# STM32L552xx register map
File version: 1.0
Registers are 32-bit, read-write, reset 0x0 unless marked. A register's access mark holds for its fields unless they carry their own. Offsets are from the block's base; [hi:lo] are bit positions.

## OPAMP12_COMMON
Base 0x40007800
Same registers: OPAMP12_COMMON_S 0x50007800
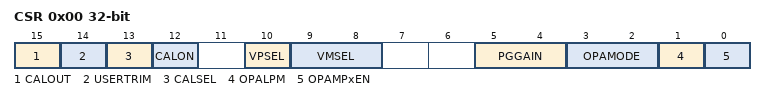
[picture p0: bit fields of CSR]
0x00 CSR — OPAMP control/status register, used for bits common to several OPAMP instances
  [15] CALOUT — Operational amplifier1 calibration output
  [14] USERTRIM — User trimming enable
    0=FACTORY (OPAMP trimming factors set to factory values); 1=USER (OPAMP trimming factors set to user values)
  [13] CALSEL — Calibration selection
  [12] CALON — Calibration mode enable
    0=FUNCTIONAL (OPAMP functional mode); 1=CALIBRATION (OPAMP calibration mode)
  [10] VPSEL — Non inverted input selection
    0=NONINVERT_IO0 (OPAMP non inverting input connected to GPIO pin (pin PA0 for OPAMP1, pin PA6 for OPAMP2)); 1=NONINV_DAC1_CH1 (OPAMP non inverting input connected to DAC1 channel1 output)
  [9:8] VMSEL — Inverting input selection
    0=IO0 (OPAMP inverting input connected to GPIO pin (valid also in PGA mode for filtering). Note: OPAMP inverting input is used with OPAMP in mode standalone or PGA with external capacitors for filtering circuit. Otherwise (OPAMP in mode follower), OPAMP inverting input is not used (not connected to GPIO pin).); 1=IO1 (OPAMP inverting input (low leakage input) connected to GPIO pin (available only on package BGA132). Note: OPAMP inverting input is used with OPAMP in mode standalone or PGA with external capacitors for filtering circuit. Otherwise (OPAMP in mode follower), OPAMP inverting input is not used (not connected to GPIO pin).); 2=CONNECT_NO (OPAMP inverting input not externally connected (intended for OPAMP in mode follower or PGA without external capacitors for filtering))
  [5:4] PGGAIN — Operational amplifier Programmable amplifier gain value
    0=GAIN_2 (OPAMP PGA gain 2); 1=GAIN_4 (OPAMP PGA gain 4); 2=GAIN_8 (OPAMP PGA gain 8); 3=GAIN_16 (OPAMP PGA gain 16)
  [3:2] OPAMODE — Operational amplifier PGA mode
    0=STANDALONE (OPAMP functional mode, OPAMP operation in standalone); 3=FOLLOWER (OPAMP functional mode, OPAMP operation in follower); 2=PGA (OPAMP functional mode, OPAMP operation in PGA)
  [1] OPALPM — Operational amplifier Low Power Mode
  [0] OPAMPxEN — OPAMP enable

## OPAMP1 — Operational Amplifier (OPAMP)
Base 0x40007800; alternate view of OPAMP12_COMMON
Same registers: OPAMP1_S 0x50007800 (alternate view of OPAMP12_COMMON_S)
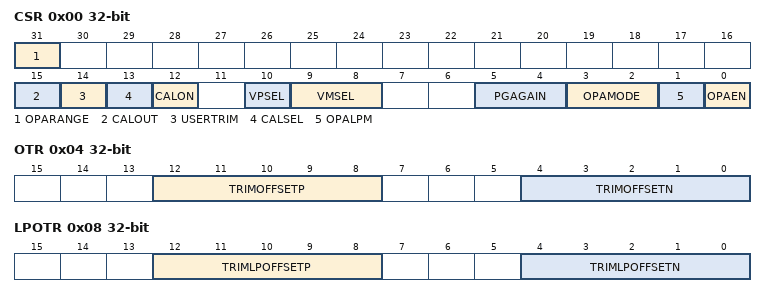
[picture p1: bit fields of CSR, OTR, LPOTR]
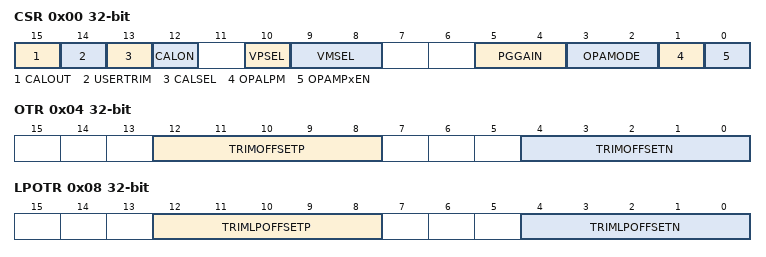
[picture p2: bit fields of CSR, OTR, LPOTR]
0x00 CSR — OPAMP control/status register
  [31] OPARANGE — Common to several OPAMP instances: Operational amplifier voltage supply range. Bit intended to be used with OPAMP common instance (OPAMP_Common_TypeDef)
    0=LOW (Power supply range low. On STM32L5 series: Vdda lower than 2.4V.); 1=HIGH (Power supply range high. On STM32L5 series: Vdda higher than 2.4V.)
  [15] CALOUT — Operational amplifier1 calibration output
  [14] USERTRIM — User trimming enable
  [13] CALSEL — Calibration selection
  [12] CALON — Calibration mode enable
  [10] VPSEL — Non inverted input selection
  [9:8] VMSEL — Inverting input selection
  [5:4] PGAGAIN — Operational amplifier1 Programmable amplifier gain value
  [3:2] OPAMODE — Operational amplifier1 PGA mode
  [1] OPALPM — Operational amplifier1 Low Power Mode
  [0] OPAEN — Operational amplifier1 Enable
0x04 OTR — OPAMP
  [12:8] TRIMOFFSETP — Trim for PMOS differential pairs
  [4:0] TRIMOFFSETN — Trim for NMOS differential pairs
0x08 LPOTR — OPAMP
  [12:8] TRIMLPOFFSETP — Trim for PMOS differential pairs
  [4:0] TRIMLPOFFSETN — Trim for NMOS differential pairs

## OPAMP — Operational Amplifier (OPAMP)
Base 0x40007800; alternate view of OPAMP12_COMMON
Same registers: OPAMP_S 0x50007800 (alternate view of OPAMP12_COMMON_S)
0x00 CSR — OPAMP control/status register
  [15] CALOUT — Operational amplifier1 calibration output
  [14] USERTRIM — User trimming enable
    0=FACTORY (OPAMP trimming factors set to factory values); 1=USER (OPAMP trimming factors set to user values)
  [13] CALSEL — Calibration selection
  [12] CALON — Calibration mode enable
    0=FUNCTIONAL (OPAMP functional mode); 1=CALIBRATION (OPAMP calibration mode)
  [10] VPSEL — Non inverted input selection
    0=NONINVERT_IO0 (OPAMP non inverting input connected to GPIO pin (pin PA0 for OPAMP1, pin PA6 for OPAMP2)); 1=NONINV_DAC1_CH1 (OPAMP non inverting input connected to DAC1 channel1 output)
  [9:8] VMSEL — Inverting input selection
    0=IO0 (OPAMP inverting input connected to GPIO pin (valid also in PGA mode for filtering). Note: OPAMP inverting input is used with OPAMP in mode standalone or PGA with external capacitors for filtering circuit. Otherwise (OPAMP in mode follower), OPAMP inverting input is not used (not connected to GPIO pin).); 1=IO1 (OPAMP inverting input (low leakage input) connected to GPIO pin (available only on package BGA132). Note: OPAMP inverting input is used with OPAMP in mode standalone or PGA with external capacitors for filtering circuit. Otherwise (OPAMP in mode follower), OPAMP inverting input is not used (not connected to GPIO pin).); 2=CONNECT_NO (OPAMP inverting input not externally connected (intended for OPAMP in mode follower or PGA without external capacitors for filtering))
  [5:4] PGGAIN — Operational amplifier Programmable amplifier gain value
    0=GAIN_2 (OPAMP PGA gain 2); 1=GAIN_4 (OPAMP PGA gain 4); 2=GAIN_8 (OPAMP PGA gain 8); 3=GAIN_16 (OPAMP PGA gain 16)
  [3:2] OPAMODE — Operational amplifier PGA mode
    0=STANDALONE (OPAMP functional mode, OPAMP operation in standalone); 3=FOLLOWER (OPAMP functional mode, OPAMP operation in follower); 2=PGA (OPAMP functional mode, OPAMP operation in PGA)
  [1] OPALPM — Operational amplifier Low Power Mode
  [0] OPAMPxEN — OPAMP enable
0x04 OTR — OPAMP
  [12:8] TRIMOFFSETP — Trim for PMOS differential pairs
  [4:0] TRIMOFFSETN — Trim for NMOS differential pairs
0x08 LPOTR — OPAMP
  [12:8] TRIMLPOFFSETP — Trim for PMOS differential pairs
  [4:0] TRIMLPOFFSETN — Trim for NMOS differential pairs
